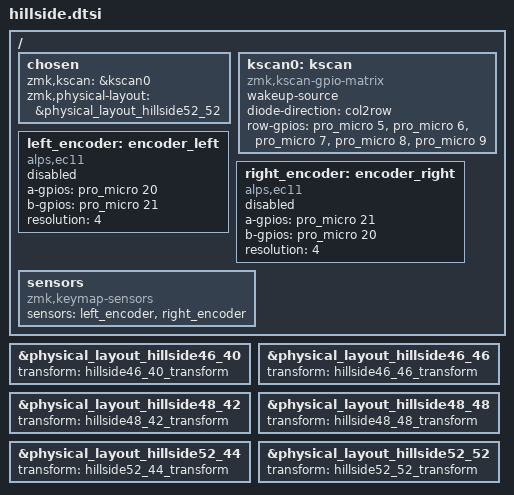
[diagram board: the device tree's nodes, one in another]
#include <dt-bindings/zmk/matrix_transform.h>

#include "layouts/hillside46_40-layout.dtsi"
#include "transforms/hillside46_40-transform.dtsi"
#include "layouts/hillside46_46-layout.dtsi"
#include "transforms/hillside46_46-transform.dtsi"

#include "layouts/hillside48_42-layout.dtsi"
#include "transforms/hillside48_42-transform.dtsi"
#include "layouts/hillside48_48-layout.dtsi"
#include "transforms/hillside48_48-transform.dtsi"

#include "layouts/hillside52_44-layout.dtsi"
#include "transforms/hillside52_44-transform.dtsi"
#include "layouts/hillside52_52-layout.dtsi"
#include "transforms/hillside52_52-transform.dtsi"

&physical_layout_hillside46_40 {
        transform = <&hillside46_40_transform>;
};

&physical_layout_hillside46_46 {
        transform = <&hillside46_46_transform>;
};

&physical_layout_hillside48_42 {
        transform = <&hillside48_42_transform>;
};

&physical_layout_hillside48_48 {
        transform = <&hillside48_48_transform>;
};

&physical_layout_hillside52_44 {
        transform = <&hillside52_44_transform>;
};

&physical_layout_hillside52_52 {
        transform = <&hillside52_52_transform>;
};

/ {
    chosen {
        zmk,kscan = &kscan0;
        zmk,physical-layout = &physical_layout_hillside52_52;
    };

    kscan0: kscan {
        compatible = "zmk,kscan-gpio-matrix";
        wakeup-source;

        diode-direction = "col2row";
        row-gpios
            = <&pro_micro 5 (GPIO_ACTIVE_HIGH | GPIO_PULL_DOWN)>
            , <&pro_micro 6 (GPIO_ACTIVE_HIGH | GPIO_PULL_DOWN)>
            , <&pro_micro 7 (GPIO_ACTIVE_HIGH | GPIO_PULL_DOWN)>
            , <&pro_micro 8 (GPIO_ACTIVE_HIGH | GPIO_PULL_DOWN)>
            , <&pro_micro 9 (GPIO_ACTIVE_HIGH | GPIO_PULL_DOWN)>
            ;

    };

    left_encoder: encoder_left {
            compatible = "alps,ec11";
            a-gpios = <&pro_micro 20 (GPIO_ACTIVE_HIGH | GPIO_PULL_UP)>;
            b-gpios = <&pro_micro 21 (GPIO_ACTIVE_HIGH | GPIO_PULL_UP)>;
            resolution = <4>;
            status = "disabled";
        };

    right_encoder: encoder_right {
            compatible = "alps,ec11";
            a-gpios = <&pro_micro 21 (GPIO_ACTIVE_HIGH | GPIO_PULL_UP)>;
            b-gpios = <&pro_micro 20 (GPIO_ACTIVE_HIGH | GPIO_PULL_UP)>;
            resolution = <4>;
            status = "disabled";
        };

    sensors {
            compatible = "zmk,keymap-sensors";
            sensors = <&left_encoder &right_encoder>;
        };

};
